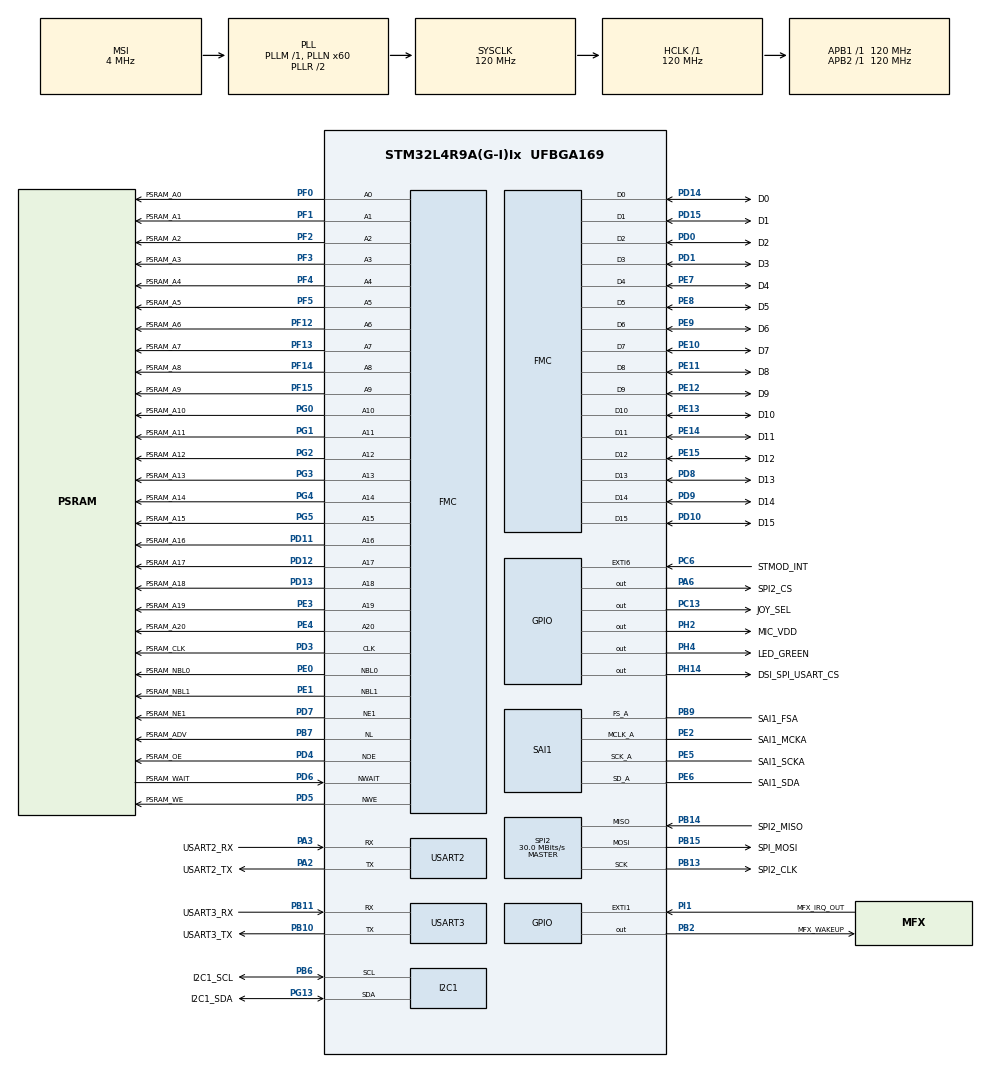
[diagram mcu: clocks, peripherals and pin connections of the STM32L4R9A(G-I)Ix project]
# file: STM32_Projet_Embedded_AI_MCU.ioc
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DSIHOST_CKN.GPIO_Label=DSI_CK_N
DSIHOST_CKN.Signal=DSIHOST_CKN
DSIHOST_CKP.GPIO_Label=DSI_CK_P
DSIHOST_CKP.Signal=DSIHOST_CKP
DSIHOST_D0N.GPIO_Label=DSI_D0_N
DSIHOST_D0N.Signal=DSIHOST_D0N
DSIHOST_D0P.GPIO_Label=DSI_D0_P
DSIHOST_D0P.Signal=DSIHOST_D0P
DSIHOST_D1N.GPIO_Label=DSI_D1_N
DSIHOST_D1N.Signal=DSIHOST_D1N
DSIHOST_D1P.GPIO_Label=DSI_D1_P
DSIHOST_D1P.Signal=DSIHOST_D1P
I2C1.Timing=0x30A175AB
Mcu.Family=STM32L4
Mcu.Name=STM32L4R9A(G-I)Ix
Mcu.Package=UFBGA169
NVIC.PriorityGroup=NVIC_PRIORITYGROUP_4
PA0.GPIO_Label=ARD_A4
PA0.Signal=ADCx_IN5
PA1.GPIO_Label=ARD_D5
PA1.Signal=S_TIM5_CH2
PA10.GPIO_Label=USB_OTGFS_ID
PA10.Signal=USB_OTG_FS_ID
PA11.GPIO_Label=USB_OTGFS_DM
PA11.Signal=USB_OTG_FS_DM
PA12.GPIO_Label=USB_OTG_FS_DP
PA12.Signal=USB_OTG_FS_DP
PA13\ (JTMS/SWDIO).GPIO_Label=SWDIO
PA13\ (JTMS/SWDIO).Mode=Serial_Wire
PA13\ (JTMS/SWDIO).Signal=SYS_JTMS-SWDIO
PA14\ (JTCK/SWCLK).GPIO_Label=SWCLK
PA14\ (JTCK/SWCLK).Mode=Serial_Wire
PA14\ (JTCK/SWCLK).Signal=SYS_JTCK-SWCLK
PA15\ (JTDI).GPIO_Label=USART3_RTS
PA15\ (JTDI).Signal=USART3_RTS
PA2.GPIO_Label=USART2_TX
PA2.Mode=Asynchronous
PA2.Signal=USART2_TX
PA3.GPIO_Label=USART2_RX
PA3.Mode=Asynchronous
PA3.Signal=USART2_RX
PA4.GPIO_Label=DCMI_HSYNC
PA4.Signal=DCMI_HSYNC
PA5.GPIO_Label=STMOD_PWM
PA5.Signal=S_TIM2_CH1
PA6.GPIO_Label=SPI2_CS
PA6.Signal=GPIO_Output
PA7.GPIO_Label=ARD_A0
PA7.Signal=ADCx_IN12
PA9.GPIO_Label=USB_OTGFS_VBUS
PA9.Signal=USB_OTG_FS_VBUS
PB0.GPIO_Label=ARD_A3
PB0.Signal=ADCx_IN15
PB10.GPIO_Label=USART3_TX
PB10.Mode=Asynchronous
PB10.Signal=USART3_TX
PB11.GPIO_Label=USART3_RX
PB11.Mode=Asynchronous
PB11.Signal=USART3_RX
PB12.GPIO_Label=DFDATIN1
PB12.Signal=S_DATAIN1DFSDM1
PB13.GPIO_Label=SPI2_CLK
PB13.Mode=Full_Duplex_Master
PB13.Signal=SPI2_SCK
PB14.GPIO_Label=SPI2_MISO
PB14.Mode=Full_Duplex_Master
PB14.Signal=SPI2_MISO
PB15.GPIO_Label=SPI_MOSI
PB15.Mode=Full_Duplex_Master
PB15.Signal=SPI2_MOSI
PB2.GPIO_Label=MFX_WAKEUP
PB2.Signal=GPIO_Output
PB3\ (JTDO/TRACESWO).GPIO_Label=SWO
PB3\ (JTDO/TRACESWO).Signal=SYS_JTDO-SWO
PB4\ (NJTRST).GPIO_Label=ARD_D6
PB4\ (NJTRST).Signal=S_TIM3_CH1
PB5.GPIO_Label=SAI1_SDB
PB5.Signal=SAI1_SD_B
PB6.GPIO_Label=I2C1_SCL
PB6.GPIO_Pu=GPIO_PULLUP
PB6.Mode=I2C
PB6.Signal=I2C1_SCL
PB7.GPIO_Label=PSRAM_ADV
PB7.Signal=FMC_NL
PB9.GPIO_Label=SAI1_FSA
PB9.Mode=SAI_A_MasterWithClock
PB9.Signal=SAI1_FS_A
PC0.GPIO_Label=ARD_D0
PC0.Signal=LPUART1_RX
PC1.GPIO_Label=ARD_D1
PC1.Signal=LPUART1_TX
PC10.GPIO_Label=uSD_D2
PC10.Signal=SDMMC1_D2
PC11.GPIO_Label=uSD_D3
PC11.Signal=SDMMC1_D3
PC12.GPIO_Label=uSD_CLK
PC12.Signal=SDMMC1_CK
PC13.GPIO_Label=JOY_SEL
PC13.Signal=GPIO_Output
PC14-OSC32_IN\ (PC14).Mode=LSE-External-Oscillator
PC14-OSC32_IN\ (PC14).Signal=RCC_OSC32_IN
PC15-OSC32_OUT\ (PC15).Mode=LSE-External-Oscillator
PC15-OSC32_OUT\ (PC15).Signal=RCC_OSC32_OUT
PC2.GPIO_Label=DF_CKOUT
PC2.Signal=S_CKOUTDFSDM1
PC3.GPIO_Label=ARD_A2
PC3.Signal=ADCx_IN4
PC4.GPIO_Label=ARD_A1
PC4.Signal=ADCx_IN13
PC6.GPIO_Label=STMOD_INT
PC6.Signal=GPXTI6
PC7.GPIO_Label=DFDATIN3
PC7.Signal=S_DATAIN3DFSDM1
PC8.GPIO_Label=uSD_D0
PC8.Signal=SDMMC1_D0
PC9.GPIO_Label=uSD_D1
PC9.Signal=SDMMC1_D1
PD0.GPIO_Label=D2
PD0.Signal=FMC_D2_DA2
PD1.GPIO_Label=D3
PD1.Signal=FMC_D3_DA3
PD10.GPIO_Label=D15
PD10.Signal=FMC_D15_DA15
PD11.GPIO_Label=PSRAM_A16
PD11.Signal=FMC_A16_CLE
PD12.GPIO_Label=PSRAM_A17
PD12.Signal=FMC_A17_ALE
PD13.GPIO_Label=PSRAM_A18
PD13.Signal=FMC_A18
PD14.GPIO_Label=D0
PD14.Signal=FMC_D0_DA0
PD15.GPIO_Label=D1
PD15.Signal=FMC_D1_DA1
PD2.GPIO_Label=uSD_CMD
PD2.Signal=SDMMC1_CMD
PD3.GPIO_Label=PSRAM_CLK
PD3.Signal=FMC_CLK
PD4.GPIO_Label=PSRAM_OE
PD4.Signal=FMC_NOE
PD5.GPIO_Label=PSRAM_WE
PD5.Signal=FMC_NWE
PD6.GPIO_Label=PSRAM_WAIT
PD6.Signal=FMC_NWAIT
PD7.GPIO_Label=PSRAM_NE1
PD7.Mode=NorPsramChipSelect1_1
PD7.Signal=FMC_NE1
PD8.GPIO_Label=D13
PD8.Signal=FMC_D13_DA13
PD9.GPIO_Label=D14
PD9.Signal=FMC_D14_DA14
PE0.GPIO_Label=PSRAM_NBL0
PE0.Signal=FMC_NBL0
PE1.GPIO_Label=PSRAM_NBL1
PE1.Signal=FMC_NBL1
PE10.GPIO_Label=D7
PE10.Signal=FMC_D7_DA7
PE11.GPIO_Label=D8
PE11.Signal=FMC_D8_DA8
PE12.GPIO_Label=D9
PE12.Signal=FMC_D9_DA9
PE13.GPIO_Label=D10
PE13.Signal=FMC_D10_DA10
PE14.GPIO_Label=D11
PE14.Signal=FMC_D11_DA11
PE15.GPIO_Label=D12
PE15.Signal=FMC_D12_DA12
PE2.GPIO_Label=SAI1_MCKA
PE2.Mode=SAI_A_MasterWithClock
PE2.Signal=SAI1_MCLK_A
PE3.GPIO_Label=PSRAM_A19
PE3.Signal=FMC_A19
PE4.GPIO_Label=PSRAM_A20
PE4.Signal=FMC_A20
PE5.GPIO_Label=SAI1_SCKA
PE5.Mode=SAI_A_MasterWithClock
PE5.Signal=SAI1_SCK_A
PE6.GPIO_Label=SAI1_SDA
PE6.Mode=SAI_A_MasterWithClock
PE6.Signal=SAI1_SD_A
PE7.GPIO_Label=D4
PE7.Signal=FMC_D4_DA4
PE8.GPIO_Label=D5
PE8.Signal=FMC_D5_DA5
PE9.GPIO_Label=D6
PE9.Signal=FMC_D6_DA6
PF0.GPIO_Label=PSRAM_A0
PF0.Signal=FMC_A0
PF1.GPIO_Label=PSRAM_A1
PF1.Signal=FMC_A1
PF11.GPIO_Label=DSI_TE
PF11.Signal=DSIHOST_TE
PF12.GPIO_Label=PSRAM_A6
PF12.Signal=FMC_A6
PF13.GPIO_Label=PSRAM_A7
PF13.Signal=FMC_A7
PF14.GPIO_Label=PSRAM_A8
PF14.Signal=FMC_A8
PF15.GPIO_Label=PSRAM_A9
PF15.Signal=FMC_A9
PF2.GPIO_Label=PSRAM_A2
PF2.Signal=FMC_A2
PF3.GPIO_Label=PSRAM_A3
PF3.Signal=FMC_A3
PF4.GPIO_Label=PSRAM_A4
PF4.Signal=FMC_A4
PF5.GPIO_Label=PSRAM_A5
PF5.Signal=FMC_A5
PG0.GPIO_Label=PSRAM_A10
PG0.Signal=FMC_A10
PG1.GPIO_Label=PSRAM_A11
PG1.Signal=FMC_A11
PG10.GPIO_Label=OCTOSPIM_P2_IO7
PG10.Signal=OCTOSPIM_P2_IO7
PG12.GPIO_Label=OCTOSPIM_P2_CS
PG12.Signal=OCTOSPIM_P2_NCS
PG13.GPIO_Label=I2C1_SDA
PG13.GPIO_Pu=GPIO_PULLUP
PG13.Mode=I2C
PG13.Signal=I2C1_SDA
PG15.GPIO_Label=OCTOSPIM_P2_DQS
PG15.Signal=OCTOSPIM_P2_DQS
PG2.GPIO_Label=PSRAM_A12
PG2.Signal=FMC_A12
PG3.GPIO_Label=PSRAM_A13
PG3.Signal=FMC_A13
PG4.GPIO_Label=PSRAM_A14
PG4.Signal=FMC_A14
PG5.GPIO_Label=PSRAM_A15
PG5.Signal=FMC_A15
PG7.GPIO_Label=ARD_15
PG7.Signal=I2C3_SCL
PG8.GPIO_Label=ARD_14
PG8.Signal=I2C3_SDA
PG9.GPIO_Label=OCTOSPIM_P2_IO6
PG9.Signal=OCTOSPIM_P2_IO6
PH0-OSC_IN\ (PH0).Mode=HSE-External-Oscillator
PH0-OSC_IN\ (PH0).Signal=RCC_OSC_IN
PH1-OSC_OUT\ (PH1).Mode=HSE-External-Oscillator
PH1-OSC_OUT\ (PH1).Signal=RCC_OSC_OUT
PH10.GPIO_Label=OCTOSPIM_P2_IO5
PH10.Signal=OCTOSPIM_P2_IO5
PH11.GPIO_Label=DCMI_D2
PH11.Signal=DCMI_D2
PH12.GPIO_Label=DCMI_D3
PH12.Signal=DCMI_D3
PH13.GPIO_Label=ARD_D9
PH13.Signal=TIM8_CH1N
PH14.GPIO_Label=DSI_SPI_USART_CS
PH14.Signal=GPIO_Output
PH2.GPIO_Label=MIC_VDD
PH2.Signal=GPIO_Output
PH4.GPIO_Label=LED_GREEN
PH4.Signal=GPIO_Output
PH5.GPIO_Label=DCMI_PIXCLK
PH5.Signal=DCMI_PIXCLK
PH8.GPIO_Label=OCTOSPI_P2_IO3
PH8.Signal=OCTOSPIM_P2_IO3
PH9.GPIO_Label=OCTOPSIM_P2_IO4
PH9.Signal=OCTOSPIM_P2_IO4
PI0.GPIO_Label=ARD_10
PI0.Signal=SPI2_NSS
PI1.GPIO_Label=MFX_IRQ_OUT
PI1.Signal=GPXTI1
PI10.GPIO_Label=OCTOSPIM_P2_IO1
PI10.Signal=OCTOSPIM_P2_IO1
PI11.GPIO_Label=OCTOSPIM_P2_IO0
PI11.Signal=OCTOSPIM_P2_IO0
PI4.GPIO_Label=DCMI_D5
PI4.Signal=DCMI_D5
PI5.GPIO_Label=DCMI_VSYNC
PI5.Signal=DCMI_VSYNC
PI6.GPIO_Label=OCTOSPIM_P2_CLK
PI6.Signal=OCTOSPIM_P2_CLK
PI7.GPIO_Label=DCMI_D7
PI7.Signal=DCMI_D7
PI9.GPIO_Label=OCTOSPIM_P2_IO2
PI9.Signal=OCTOSPIM_P2_IO2
ProjectManager.HeapSize=0x800
ProjectManager.StackSize=0x800
ProjectManager.TargetToolchain=STM32CubeIDE
RCC.ADCFreq_Value=32000000
RCC.AHBFreq_Value=120000000
RCC.APB1Freq_Value=120000000
RCC.APB1TimFreq_Value=120000000
RCC.APB2Freq_Value=120000000
RCC.APB2TimFreq_Value=120000000
RCC.CK48CLockSelection=RCC_USBCLKSOURCE_HSI48
RCC.CortexFreq_Value=120000000
RCC.HCLKFreq_Value=120000000
RCC.HSE_VALUE=16000000
RCC.HSI48_VALUE=48000000
RCC.HSI_VALUE=16000000
RCC.MSI_VALUE=4000000
RCC.PLLDSINDIV=32
RCC.PLLN=60
RCC.PLLP=RCC_PLLP_DIV5
RCC.PLLSAI1N=16
RCC.SYSCLKFreq_VALUE=120000000
RCC.SYSCLKSource=RCC_SYSCLKSOURCE_PLLCLK
RCC.USBFreq_Value=48000000
RCC.VCOOutputFreq_Value=240000000
SAI1.Instance-SAI_A_MasterWithClock=SAI$Index_Block_A
SAI1.MClockEnable-SAI_A_MasterWithClock=SAI_MASTERCLOCK_ENABLE
SAI1.Synchro-SAI_A_MasterWithClock=SAI_ASYNCHRONOUS
SAI1.VirtualMode-SAI_A_MasterWithClock=VM_MASTER
SH.ADCx_IN12.0=ADC1_IN12
SH.ADCx_IN13.0=ADC1_IN13
SH.ADCx_IN15.0=ADC1_IN15
SH.ADCx_IN4.0=ADC1_IN4
SH.ADCx_IN5.0=ADC1_IN5
SH.FMC_A0.0=FMC_A0,21b-a1
SH.FMC_A1.0=FMC_A1,21b-a1
SH.FMC_A10.0=FMC_A10,21b-a1
SH.FMC_A11.0=FMC_A11,21b-a1
SH.FMC_A12.0=FMC_A12,21b-a1
SH.FMC_A13.0=FMC_A13,21b-a1
SH.FMC_A14.0=FMC_A14,21b-a1
SH.FMC_A15.0=FMC_A15,21b-a1
SH.FMC_A16_CLE.0=FMC_A16,21b-a1
SH.FMC_A17_ALE.0=FMC_A17,21b-a1
SH.FMC_A18.0=FMC_A18,21b-a1
SH.FMC_A19.0=FMC_A19,21b-a1
SH.FMC_A2.0=FMC_A2,21b-a1
SH.FMC_A20.0=FMC_A20,21b-a1
SH.FMC_A3.0=FMC_A3,21b-a1
SH.FMC_A4.0=FMC_A4,21b-a1
SH.FMC_A5.0=FMC_A5,21b-a1
SH.FMC_A6.0=FMC_A6,21b-a1
SH.FMC_A7.0=FMC_A7,21b-a1
SH.FMC_A8.0=FMC_A8,21b-a1
SH.FMC_A9.0=FMC_A9,21b-a1
SH.FMC_CLK.0=FMC_CLK,BurstReadWrite1
SH.FMC_D0_DA0.0=FMC_D0,16b-d1
SH.FMC_D10_DA10.0=FMC_D10,16b-d1
SH.FMC_D11_DA11.0=FMC_D11,16b-d1
SH.FMC_D12_DA12.0=FMC_D12,16b-d1
SH.FMC_D13_DA13.0=FMC_D13,16b-d1
SH.FMC_D14_DA14.0=FMC_D14,16b-d1
SH.FMC_D15_DA15.0=FMC_D15,16b-d1
SH.FMC_D1_DA1.0=FMC_D1,16b-d1
SH.FMC_D2_DA2.0=FMC_D2,16b-d1
SH.FMC_D3_DA3.0=FMC_D3,16b-d1
SH.FMC_D4_DA4.0=FMC_D4,16b-d1
SH.FMC_D5_DA5.0=FMC_D5,16b-d1
SH.FMC_D6_DA6.0=FMC_D6,16b-d1
SH.FMC_D7_DA7.0=FMC_D7,16b-d1
SH.FMC_D8_DA8.0=FMC_D8,16b-d1
SH.FMC_D9_DA9.0=FMC_D9,16b-d1
SH.FMC_NBL0.0=FMC_NBL0,2ByteEnable1
SH.FMC_NBL1.0=FMC_NBL1,2ByteEnable1
SH.FMC_NL.0=FMC_NL,AddressValid1
SH.FMC_NOE.0=FMC_NOE,Psram1
SH.FMC_NWAIT.0=FMC_NWAIT,SynchronousWait1
SH.FMC_NWE.0=FMC_NWE,Psram1
SH.S_CKOUTDFSDM1.0=DFSDM1_CKOUT
SH.S_DATAIN1DFSDM1.0=DFSDM1_DATIN1
SH.S_DATAIN3DFSDM1.0=DFSDM1_DATIN3
SH.S_TIM2_CH1.0=TIM2_CH1
SH.S_TIM3_CH1.0=TIM3_CH1
SH.S_TIM5_CH2.0=TIM5_CH2
SPI2.BaudRatePrescaler=SPI_BAUDRATEPRESCALER_4
SPI2.CalculateBaudRate=30.0 MBits/s
SPI2.Direction=SPI_DIRECTION_2LINES
SPI2.Mode=SPI_MODE_MASTER
SPI2.VirtualType=VM_MASTER
STMicroelectronics.X-CUBE-AI.10.2.1.ActivationBufferSizeList=8164
STMicroelectronics.X-CUBE-AI.10.2.1.ActivationBuffers=pool0
STMicroelectronics.X-CUBE-AI.10.2.1.ActivationNames=pool0
STMicroelectronics.X-CUBE-AI.10.2.1.ActivationSizes=AI_MLP_MNIST_PROJET_DATA_ACTIVATION_1_SIZE
STMicroelectronics.X-CUBE-AI.10.2.1.ApplicationCcDeviceJjApplication=ApplicationTemplate
STMicroelectronics.X-CUBE-AI.10.2.1.HeapSize=0x800
STMicroelectronics.X-CUBE-AI.10.2.1.InternalRamActivationBufferMaxSize=AI_MLP_MNIST_PROJET_DATA_ACTIVATIONS_SIZE
STMicroelectronics.X-CUBE-AI.10.2.1.LatestDirectoryUsed-bec54e313666f811863a96fbc236fbb6e126a35f0ca2705b14571c2bcad92c82=C\:\\Users\\foltz\\Documents\\ISMIN\\3A\\Embedded_Systems\\Embedded_Neural_Network_on_MCU
STMicroelectronics.X-CUBE-AI.10.2.1.MaximumNumberOfInputLayer=1
STMicroelectronics.X-CUBE-AI.10.2.1.MaximumNumberOfOutputLayer=1
STMicroelectronics.X-CUBE-AI.10.2.1.MaximumSizeOfInputLayer=1
STMicroelectronics.X-CUBE-AI.10.2.1.MaximumSizeOfOutputLayer=1
STMicroelectronics.X-CUBE-AI.10.2.1.ModelActualCompression-bec54e313666f811863a96fbc236fbb6e126a35f0ca2705b14571c2bcad92c82=0.0
STMicroelectronics.X-CUBE-AI.10.2.1.ModelCompression-bec54e313666f811863a96fbc236fbb6e126a35f0ca2705b14571c2bcad92c82=Medium
STMicroelectronics.X-CUBE-AI.10.2.1.ModelFlashOccupation-bec54e313666f811863a96fbc236fbb6e126a35f0ca2705b14571c2bcad92c82=334080
STMicroelectronics.X-CUBE-AI.10.2.1.ModelHashList=bec54e313666f811863a96fbc236fbb6e126a35f0ca2705b14571c2bcad92c82
STMicroelectronics.X-CUBE-AI.10.2.1.ModelKind-bec54e313666f811863a96fbc236fbb6e126a35f0ca2705b14571c2bcad92c82=KERAS
STMicroelectronics.X-CUBE-AI.10.2.1.ModelMacc-bec54e313666f811863a96fbc236fbb6e126a35f0ca2705b14571c2bcad92c82=576160
STMicroelectronics.X-CUBE-AI.10.2.1.ModelName-bec54e313666f811863a96fbc236fbb6e126a35f0ca2705b14571c2bcad92c82=mlp_mnist_projet
STMicroelectronics.X-CUBE-AI.10.2.1.ModelNameList=mlp_mnist_projet
STMicroelectronics.X-CUBE-AI.10.2.1.ModelRamOccupation-bec54e313666f811863a96fbc236fbb6e126a35f0ca2705b14571c2bcad92c82=8164
STMicroelectronics.X-CUBE-AI.10.2.1.ModelStructureFile-bec54e313666f811863a96fbc236fbb6e126a35f0ca2705b14571c2bcad92c82=C\:\\Users\\foltz\\Documents\\ISMIN\\3A\\Embedded_Systems\\Embedded_Neural_Network_on_MCU\\Projet_Embedded_AI_MCU\\models\\5dense-mnist-10class-finetuned.h5
STMicroelectronics.X-CUBE-AI.10.2.1.ModelType-bec54e313666f811863a96fbc236fbb6e126a35f0ca2705b14571c2bcad92c82=STM32Cube.AI MCU runtime
STMicroelectronics.X-CUBE-AI.10.2.1.ReadyForCodeGeneration=true
STMicroelectronics.X-CUBE-AI.10.2.1.StackSize=0x800
STMicroelectronics.X-CUBE-AI.10.2.1.ValidationInputFile-bec54e313666f811863a96fbc236fbb6e126a35f0ca2705b14571c2bcad92c82=C\:\\Users\\foltz\\Documents\\ISMIN\\3A\\Embedded_Systems\\Embedded_Neural_Network_on_MCU\\MNIST_xtest_NN_C2_16_10.npy
STMicroelectronics.X-CUBE-AI.10.2.1.ValidationInputFileHistory-bec54e313666f811863a96fbc236fbb6e126a35f0ca2705b14571c2bcad92c82=C\:\\Users\\foltz\\Documents\\ISMIN\\3A\\Embedded_Systems\\Embedded_Neural_Network_on_MCU\\MNIST_xtest_NN_C2_16_10.npy,C\:\\Users\\foltz\\Documents\\ISMIN\\3A\\Embedded_Systems\\Embedded_Neural_Network_on_MCU\\MNIST_xtest_NN_C2_16_10.npy
STMicroelectronics.X-CUBE-AI.10.2.1.ValidationOutputFile-bec54e313666f811863a96fbc236fbb6e126a35f0ca2705b14571c2bcad92c82=C\:\\Users\\foltz\\Documents\\ISMIN\\3A\\Embedded_Systems\\Embedded_Neural_Network_on_MCU\\MNIST_ytest_NN_C2_16_10.npy
STMicroelectronics.X-CUBE-AI.10.2.1.ValidationOutputFileHistory-bec54e313666f811863a96fbc236fbb6e126a35f0ca2705b14571c2bcad92c82=C\:\\Users\\foltz\\Documents\\ISMIN\\3A\\Embedded_Systems\\Embedded_Neural_Network_on_MCU\\MNIST_ytest_NN_C2_16_10.npy,C\:\\Users\\foltz\\Documents\\ISMIN\\3A\\Embedded_Systems\\Embedded_Neural_Network_on_MCU\\MNIST_ytest_NN_C2_16_10.npy
STMicroelectronics.X-CUBE-AI.10.2.1.WorkingBufferStartAddrList=0xFFFFFFFF
STMicroelectronics.X-CUBE-AI.10.2.1.XAaCUBEAaAICcArtificialOoIntelligenceJjCore=true
STMicroelectronics.X-CUBE-AI.10.2.1.copyWeightToRam=false
STMicroelectronics.X-CUBE-AI.10.2.1.copyWeightToRam-bec54e313666f811863a96fbc236fbb6e126a35f0ca2705b14571c2bcad92c82=false
STMicroelectronics.X-CUBE-AI.10.2.1.customLayerConfigEnabled=false
STMicroelectronics.X-CUBE-AI.10.2.1.customLayerConfigEnabled-bec54e313666f811863a96fbc236fbb6e126a35f0ca2705b14571c2bcad92c82=false
STMicroelectronics.X-CUBE-AI.10.2.1.noOnnxIoTranspose=false
STMicroelectronics.X-CUBE-AI.10.2.1.noOnnxIoTranspose-bec54e313666f811863a96fbc236fbb6e126a35f0ca2705b14571c2bcad92c82=false
STMicroelectronics.X-CUBE-AI.10.2.1.useInputAllocation=true
STMicroelectronics.X-CUBE-AI.10.2.1.useInputAllocation-bec54e313666f811863a96fbc236fbb6e126a35f0ca2705b14571c2bcad92c82=true
STMicroelectronics.X-CUBE-AI.10.2.1.useOutputAllocation=true
STMicroelectronics.X-CUBE-AI.10.2.1.useOutputAllocation-bec54e313666f811863a96fbc236fbb6e126a35f0ca2705b14571c2bcad92c82=true
USART2.VirtualMode-Asynchronous=VM_ASYNC
USART3.VirtualMode-Asynchronous=VM_ASYNC
VP_STMicroelectronics.X-CUBE-AI_VS_ArtificialOoIntelligenceJjXAaCUBEAaAI_10.2.1.Mode=ArtificialOoIntelligenceJjXAaCUBEAaAI
VP_STMicroelectronics.X-CUBE-AI_VS_DeviceJjApplication_10.2.1.Mode=DeviceJjApplication
board=STM32L4R9I-DISCO

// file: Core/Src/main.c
/* USER CODE BEGIN Header */
/**
  ******************************************************************************
  * @file           : main.c
  * @brief          : Main program body
  ******************************************************************************
  * @attention
  *
  * Copyright (c) 2026 STMicroelectronics.
  * All rights reserved.
  *
  * This software is licensed under terms that can be found in the LICENSE file
  * in the root directory of this software component.
  * If no LICENSE file comes with this software, it is provided AS-IS.
  *
  ******************************************************************************
  */
/* USER CODE END Header */
#include "main.h"
#include "app_x-cube-ai.h"

I2C_HandleTypeDef hi2c1;

SAI_HandleTypeDef hsai_BlockA1;

SPI_HandleTypeDef hspi2;

UART_HandleTypeDef huart2;
UART_HandleTypeDef huart3;

SRAM_HandleTypeDef hsram1;

void SystemClock_Config(void);
static void MX_GPIO_Init(void);
static void MX_FMC_Init(void);
static void MX_I2C1_Init(void);
static void MX_SAI1_Init(void);
static void MX_SPI2_Init(void);
static void MX_USART2_UART_Init(void);
static void MX_USART3_UART_Init(void);
/* USER CODE BEGIN PFP */
void AIfES_Init(void);
void AIfES_Process(void);
/* USER CODE END PFP */

int main(void)
{

  /* MCU Configuration--------------------------------------------------------*/

  /* Reset of all peripherals, Initializes the Flash interface and the Systick. */
  HAL_Init();

  /* Configure the system clock */
  SystemClock_Config();

  /* Initialize all configured peripherals */
  MX_GPIO_Init();
  MX_FMC_Init();
  MX_I2C1_Init();
  MX_SAI1_Init();
  MX_SPI2_Init();
  MX_USART2_UART_Init();
  MX_USART3_UART_Init();
  MX_X_CUBE_AI_Init();
  /* USER CODE BEGIN 2 */
  AIfES_Init();
  AIfES_Process(); //ne rend jamais la main donc pas besoin de rentrer dans le while, la focntion contient sa propre boucle infinie

  /* USER CODE END 2 */

  /* Infinite loop */
  while (1)
  {

  MX_X_CUBE_AI_Process();
  }
}

void SystemClock_Config(void)
{
  RCC_OscInitTypeDef RCC_OscInitStruct = {0};
  RCC_ClkInitTypeDef RCC_ClkInitStruct = {0};

  /** Configure the main internal regulator output voltage
  */
  if (HAL_PWREx_ControlVoltageScaling(PWR_REGULATOR_VOLTAGE_SCALE1_BOOST) != HAL_OK)
  {
    Error_Handler();
  }

  /** Initializes the RCC Oscillators according to the specified parameters
  * in the RCC_OscInitTypeDef structure.
  */
  RCC_OscInitStruct.OscillatorType = RCC_OSCILLATORTYPE_MSI;
  RCC_OscInitStruct.MSIState = RCC_MSI_ON;
  RCC_OscInitStruct.MSICalibrationValue = 0;
  RCC_OscInitStruct.MSIClockRange = RCC_MSIRANGE_6;
  RCC_OscInitStruct.PLL.PLLState = RCC_PLL_ON;
  RCC_OscInitStruct.PLL.PLLSource = RCC_PLLSOURCE_MSI;
  RCC_OscInitStruct.PLL.PLLM = 1;
  RCC_OscInitStruct.PLL.PLLN = 60;
  RCC_OscInitStruct.PLL.PLLP = RCC_PLLP_DIV5;
  RCC_OscInitStruct.PLL.PLLQ = RCC_PLLQ_DIV2;
  RCC_OscInitStruct.PLL.PLLR = RCC_PLLR_DIV2;
  if (HAL_RCC_OscConfig(&RCC_OscInitStruct) != HAL_OK)
  {
    Error_Handler();
  }

  /** Initializes the CPU, AHB and APB buses clocks
  */
  RCC_ClkInitStruct.ClockType = RCC_CLOCKTYPE_HCLK|RCC_CLOCKTYPE_SYSCLK
                              |RCC_CLOCKTYPE_PCLK1|RCC_CLOCKTYPE_PCLK2;
  RCC_ClkInitStruct.SYSCLKSource = RCC_SYSCLKSOURCE_PLLCLK;
  RCC_ClkInitStruct.AHBCLKDivider = RCC_SYSCLK_DIV1;
  RCC_ClkInitStruct.APB1CLKDivider = RCC_HCLK_DIV1;
  RCC_ClkInitStruct.APB2CLKDivider = RCC_HCLK_DIV1;

  if (HAL_RCC_ClockConfig(&RCC_ClkInitStruct, FLASH_LATENCY_5) != HAL_OK)
  {
    Error_Handler();
  }
}

static void MX_I2C1_Init(void)
{

  hi2c1.Instance = I2C1;
  hi2c1.Init.Timing = 0x30A175AB;
  hi2c1.Init.OwnAddress1 = 0;
  hi2c1.Init.AddressingMode = I2C_ADDRESSINGMODE_7BIT;
  hi2c1.Init.DualAddressMode = I2C_DUALADDRESS_DISABLE;
  hi2c1.Init.OwnAddress2 = 0;
  hi2c1.Init.OwnAddress2Masks = I2C_OA2_NOMASK;
  hi2c1.Init.GeneralCallMode = I2C_GENERALCALL_DISABLE;
  hi2c1.Init.NoStretchMode = I2C_NOSTRETCH_DISABLE;
  if (HAL_I2C_Init(&hi2c1) != HAL_OK)
  {
    Error_Handler();
  }

  /** Configure Analogue filter
  */
  if (HAL_I2CEx_ConfigAnalogFilter(&hi2c1, I2C_ANALOGFILTER_ENABLE) != HAL_OK)
  {
    Error_Handler();
  }

  /** Configure Digital filter
  */
  if (HAL_I2CEx_ConfigDigitalFilter(&hi2c1, 0) != HAL_OK)
  {
    Error_Handler();
  }

}

static void MX_SAI1_Init(void)
{

  hsai_BlockA1.Instance = SAI1_Block_A;
  hsai_BlockA1.Init.Protocol = SAI_FREE_PROTOCOL;
  hsai_BlockA1.Init.AudioMode = SAI_MODEMASTER_TX;
  hsai_BlockA1.Init.DataSize = SAI_DATASIZE_8;
  hsai_BlockA1.Init.FirstBit = SAI_FIRSTBIT_MSB;
  hsai_BlockA1.Init.ClockStrobing = SAI_CLOCKSTROBING_FALLINGEDGE;
  hsai_BlockA1.Init.Synchro = SAI_ASYNCHRONOUS;
  hsai_BlockA1.Init.OutputDrive = SAI_OUTPUTDRIVE_DISABLE;
  hsai_BlockA1.Init.NoDivider = SAI_MASTERDIVIDER_ENABLE;
  hsai_BlockA1.Init.MckOverSampling = SAI_MCK_OVERSAMPLING_DISABLE;
  hsai_BlockA1.Init.FIFOThreshold = SAI_FIFOTHRESHOLD_EMPTY;
  hsai_BlockA1.Init.AudioFrequency = SAI_AUDIO_FREQUENCY_192K;
  hsai_BlockA1.Init.SynchroExt = SAI_SYNCEXT_DISABLE;
  hsai_BlockA1.Init.MonoStereoMode = SAI_STEREOMODE;
  hsai_BlockA1.Init.CompandingMode = SAI_NOCOMPANDING;
  hsai_BlockA1.Init.TriState = SAI_OUTPUT_NOTRELEASED;
  hsai_BlockA1.Init.PdmInit.Activation = DISABLE;
  hsai_BlockA1.Init.PdmInit.MicPairsNbr = 0;
  hsai_BlockA1.Init.PdmInit.ClockEnable = SAI_PDM_CLOCK1_ENABLE;
  hsai_BlockA1.FrameInit.FrameLength = 8;
  hsai_BlockA1.FrameInit.ActiveFrameLength = 1;
  hsai_BlockA1.FrameInit.FSDefinition = SAI_FS_STARTFRAME;
  hsai_BlockA1.FrameInit.FSPolarity = SAI_FS_ACTIVE_LOW;
  hsai_BlockA1.FrameInit.FSOffset = SAI_FS_FIRSTBIT;
  hsai_BlockA1.SlotInit.FirstBitOffset = 0;
  hsai_BlockA1.SlotInit.SlotSize = SAI_SLOTSIZE_DATASIZE;
  hsai_BlockA1.SlotInit.SlotNumber = 1;
  hsai_BlockA1.SlotInit.SlotActive = 0x00000000;
  if (HAL_SAI_Init(&hsai_BlockA1) != HAL_OK)
  {
    Error_Handler();
  }

}

static void MX_SPI2_Init(void)
{

  /* SPI2 parameter configuration*/
  hspi2.Instance = SPI2;
  hspi2.Init.Mode = SPI_MODE_MASTER;
  hspi2.Init.Direction = SPI_DIRECTION_2LINES;
  hspi2.Init.DataSize = SPI_DATASIZE_4BIT;
  hspi2.Init.CLKPolarity = SPI_POLARITY_LOW;
  hspi2.Init.CLKPhase = SPI_PHASE_1EDGE;
  hspi2.Init.NSS = SPI_NSS_SOFT;
  hspi2.Init.BaudRatePrescaler = SPI_BAUDRATEPRESCALER_4;
  hspi2.Init.FirstBit = SPI_FIRSTBIT_MSB;
  hspi2.Init.TIMode = SPI_TIMODE_DISABLE;
  hspi2.Init.CRCCalculation = SPI_CRCCALCULATION_DISABLE;
  hspi2.Init.CRCPolynomial = 7;
  hspi2.Init.CRCLength = SPI_CRC_LENGTH_DATASIZE;
  hspi2.Init.NSSPMode = SPI_NSS_PULSE_ENABLE;
  if (HAL_SPI_Init(&hspi2) != HAL_OK)
  {
    Error_Handler();
  }

}

static void MX_USART2_UART_Init(void)
{

  huart2.Instance = USART2;
  huart2.Init.BaudRate = 115200;
  huart2.Init.WordLength = UART_WORDLENGTH_8B;
  huart2.Init.StopBits = UART_STOPBITS_1;
  huart2.Init.Parity = UART_PARITY_NONE;
  huart2.Init.Mode = UART_MODE_TX_RX;
  huart2.Init.HwFlowCtl = UART_HWCONTROL_NONE;
  huart2.Init.OverSampling = UART_OVERSAMPLING_16;
  huart2.Init.OneBitSampling = UART_ONE_BIT_SAMPLE_DISABLE;
  huart2.Init.ClockPrescaler = UART_PRESCALER_DIV1;
  huart2.AdvancedInit.AdvFeatureInit = UART_ADVFEATURE_NO_INIT;
  if (HAL_UART_Init(&huart2) != HAL_OK)
  {
    Error_Handler();
  }
  if (HAL_UARTEx_SetTxFifoThreshold(&huart2, UART_TXFIFO_THRESHOLD_1_8) != HAL_OK)
  {
    Error_Handler();
  }
  if (HAL_UARTEx_SetRxFifoThreshold(&huart2, UART_RXFIFO_THRESHOLD_1_8) != HAL_OK)
  {
    Error_Handler();
  }
  if (HAL_UARTEx_DisableFifoMode(&huart2) != HAL_OK)
  {
    Error_Handler();
  }

}

static void MX_USART3_UART_Init(void)
{

  huart3.Instance = USART3;
  huart3.Init.BaudRate = 115200;
  huart3.Init.WordLength = UART_WORDLENGTH_8B;
  huart3.Init.StopBits = UART_STOPBITS_1;
  huart3.Init.Parity = UART_PARITY_NONE;
  huart3.Init.Mode = UART_MODE_TX_RX;
  huart3.Init.HwFlowCtl = UART_HWCONTROL_NONE;
  huart3.Init.OverSampling = UART_OVERSAMPLING_16;
  huart3.Init.OneBitSampling = UART_ONE_BIT_SAMPLE_DISABLE;
  huart3.Init.ClockPrescaler = UART_PRESCALER_DIV1;
  huart3.AdvancedInit.AdvFeatureInit = UART_ADVFEATURE_NO_INIT;
  if (HAL_UART_Init(&huart3) != HAL_OK)
  {
    Error_Handler();
  }
  if (HAL_UARTEx_SetTxFifoThreshold(&huart3, UART_TXFIFO_THRESHOLD_1_8) != HAL_OK)
  {
    Error_Handler();
  }
  if (HAL_UARTEx_SetRxFifoThreshold(&huart3, UART_RXFIFO_THRESHOLD_1_8) != HAL_OK)
  {
    Error_Handler();
  }
  if (HAL_UARTEx_DisableFifoMode(&huart3) != HAL_OK)
  {
    Error_Handler();
  }

}

/* FMC initialization function */
static void MX_FMC_Init(void)
{

  FMC_NORSRAM_TimingTypeDef Timing = {0};

  /** Perform the SRAM1 memory initialization sequence
  */
  hsram1.Instance = FMC_NORSRAM_DEVICE;
  hsram1.Extended = FMC_NORSRAM_EXTENDED_DEVICE;
  /* hsram1.Init */
  hsram1.Init.NSBank = FMC_NORSRAM_BANK1;
  hsram1.Init.DataAddressMux = FMC_DATA_ADDRESS_MUX_DISABLE;
  hsram1.Init.MemoryType = FMC_MEMORY_TYPE_PSRAM;
  hsram1.Init.MemoryDataWidth = FMC_NORSRAM_MEM_BUS_WIDTH_16;
  hsram1.Init.BurstAccessMode = FMC_BURST_ACCESS_MODE_ENABLE;
  hsram1.Init.WaitSignalPolarity = FMC_WAIT_SIGNAL_POLARITY_LOW;
  hsram1.Init.WaitSignalActive = FMC_WAIT_TIMING_BEFORE_WS;
  hsram1.Init.WriteOperation = FMC_WRITE_OPERATION_DISABLE;
  hsram1.Init.WaitSignal = FMC_WAIT_SIGNAL_ENABLE;
  hsram1.Init.ExtendedMode = FMC_EXTENDED_MODE_DISABLE;
  hsram1.Init.AsynchronousWait = FMC_ASYNCHRONOUS_WAIT_DISABLE;
  hsram1.Init.WriteBurst = FMC_WRITE_BURST_ENABLE;
  hsram1.Init.ContinuousClock = FMC_CONTINUOUS_CLOCK_SYNC_ONLY;
  hsram1.Init.WriteFifo = FMC_WRITE_FIFO_ENABLE;
  hsram1.Init.NBLSetupTime = 0;
  hsram1.Init.PageSize = FMC_PAGE_SIZE_NONE;
  /* Timing */
  Timing.AddressSetupTime = 15;
  Timing.AddressHoldTime = 15;
  Timing.DataSetupTime = 255;
  Timing.DataHoldTime = 0;
  Timing.BusTurnAroundDuration = 15;
  Timing.CLKDivision = 16;
  Timing.DataLatency = 2;
  Timing.AccessMode = FMC_ACCESS_MODE_A;
  /* ExtTiming */

  if (HAL_SRAM_Init(&hsram1, &Timing, NULL) != HAL_OK)
  {
    Error_Handler( );
  }

}

static void MX_GPIO_Init(void)
{
  GPIO_InitTypeDef GPIO_InitStruct = {0};

  /* GPIO Ports Clock Enable */
  __HAL_RCC_GPIOI_CLK_ENABLE();
  __HAL_RCC_GPIOH_CLK_ENABLE();
  __HAL_RCC_GPIOE_CLK_ENABLE();
  __HAL_RCC_GPIOB_CLK_ENABLE();
  __HAL_RCC_GPIOA_CLK_ENABLE();
  __HAL_RCC_GPIOG_CLK_ENABLE();
  HAL_PWREx_EnableVddIO2();
  __HAL_RCC_GPIOD_CLK_ENABLE();
  __HAL_RCC_GPIOC_CLK_ENABLE();
  __HAL_RCC_GPIOF_CLK_ENABLE();

  /*Configure GPIO pin Output Level */
  HAL_GPIO_WritePin(GPIOH, MIC_VDD_Pin|DSI_SPI_USART_CS_Pin|LED_GREEN_Pin, GPIO_PIN_RESET);

  /*Configure GPIO pin Output Level */
  HAL_GPIO_WritePin(JOY_SEL_GPIO_Port, JOY_SEL_Pin, GPIO_PIN_RESET);

  /*Configure GPIO pin Output Level */
  HAL_GPIO_WritePin(SPI2_CS_GPIO_Port, SPI2_CS_Pin, GPIO_PIN_RESET);

  /*Configure GPIO pin Output Level */
  HAL_GPIO_WritePin(MFX_WAKEUP_GPIO_Port, MFX_WAKEUP_Pin, GPIO_PIN_RESET);

  /*Configure GPIO pins : OCTOSPIM_P2_IO1_Pin OCTOSPIM_P2_IO2_Pin OCTOSPIM_P2_CLK_Pin OCTOSPIM_P2_IO0_Pin */
  GPIO_InitStruct.Pin = OCTOSPIM_P2_IO1_Pin|OCTOSPIM_P2_IO2_Pin|OCTOSPIM_P2_CLK_Pin|OCTOSPIM_P2_IO0_Pin;
  GPIO_InitStruct.Mode = GPIO_MODE_AF_PP;
  GPIO_InitStruct.Pull = GPIO_NOPULL;
  GPIO_InitStruct.Speed = GPIO_SPEED_FREQ_VERY_HIGH;
  GPIO_InitStruct.Alternate = GPIO_AF5_OCTOSPIM_P2;
  HAL_GPIO_Init(GPIOI, &GPIO_InitStruct);

  /*Configure GPIO pins : MIC_VDD_Pin DSI_SPI_USART_CS_Pin LED_GREEN_Pin */
  GPIO_InitStruct.Pin = MIC_VDD_Pin|DSI_SPI_USART_CS_Pin|LED_GREEN_Pin;
  GPIO_InitStruct.Mode = GPIO_MODE_OUTPUT_PP;
  GPIO_InitStruct.Pull = GPIO_NOPULL;
  GPIO_InitStruct.Speed = GPIO_SPEED_FREQ_LOW;
  HAL_GPIO_Init(GPIOH, &GPIO_InitStruct);

  /*Configure GPIO pin : ARD_D6_Pin */
  GPIO_InitStruct.Pin = ARD_D6_Pin;
  GPIO_InitStruct.Mode = GPIO_MODE_AF_PP;
  GPIO_InitStruct.Pull = GPIO_NOPULL;
  GPIO_InitStruct.Speed = GPIO_SPEED_FREQ_LOW;
  GPIO_InitStruct.Alternate = GPIO_AF2_TIM3;
  HAL_GPIO_Init(ARD_D6_GPIO_Port, &GPIO_InitStruct);

  /*Configure GPIO pins : DCMI_D7_Pin DCMI_D5_Pin DCMI_VSYNC_Pin */
  GPIO_InitStruct.Pin = DCMI_D7_Pin|DCMI_D5_Pin|DCMI_VSYNC_Pin;
  GPIO_InitStruct.Mode = GPIO_MODE_AF_PP;
  GPIO_InitStruct.Pull = GPIO_NOPULL;
  GPIO_InitStruct.Speed = GPIO_SPEED_FREQ_LOW;
  GPIO_InitStruct.Alternate = GPIO_AF10_DCMI;
  HAL_GPIO_Init(GPIOI, &GPIO_InitStruct);

  /*Configure GPIO pins : OCTOSPIM_P2_IO6_Pin OCTOSPIM_P2_DQS_Pin OCTOSPIM_P2_IO7_Pin OCTOSPIM_P2_CS_Pin */
  GPIO_InitStruct.Pin = OCTOSPIM_P2_IO6_Pin|OCTOSPIM_P2_DQS_Pin|OCTOSPIM_P2_IO7_Pin|OCTOSPIM_P2_CS_Pin;
  GPIO_InitStruct.Mode = GPIO_MODE_AF_PP;
  GPIO_InitStruct.Pull = GPIO_NOPULL;
  GPIO_InitStruct.Speed = GPIO_SPEED_FREQ_VERY_HIGH;
  GPIO_InitStruct.Alternate = GPIO_AF5_OCTOSPIM_P2;
  HAL_GPIO_Init(GPIOG, &GPIO_InitStruct);

  /*Configure GPIO pin : MFX_IRQ_OUT_Pin */
  GPIO_InitStruct.Pin = MFX_IRQ_OUT_Pin;
  GPIO_InitStruct.Mode = GPIO_MODE_IT_RISING;
  GPIO_InitStruct.Pull = GPIO_NOPULL;
  HAL_GPIO_Init(MFX_IRQ_OUT_GPIO_Port, &GPIO_InitStruct);

  /*Configure GPIO pins : DCMI_D3_Pin DCMI_PIXCLK_Pin DCMI_D2_Pin */
  GPIO_InitStruct.Pin = DCMI_D3_Pin|DCMI_PIXCLK_Pin|DCMI_D2_Pin;
  GPIO_InitStruct.Mode = GPIO_MODE_AF_PP;
  GPIO_InitStruct.Pull = GPIO_NOPULL;
  GPIO_InitStruct.Speed = GPIO_SPEED_FREQ_LOW;
  GPIO_InitStruct.Alternate = GPIO_AF10_DCMI;
  HAL_GPIO_Init(GPIOH, &GPIO_InitStruct);

  /*Configure GPIO pin : ARD_D9_Pin */
  GPIO_InitStruct.Pin = ARD_D9_Pin;
  GPIO_InitStruct.Mode = GPIO_MODE_AF_PP;
  GPIO_InitStruct.Pull = GPIO_NOPULL;
  GPIO_InitStruct.Speed = GPIO_SPEED_FREQ_LOW;
  GPIO_InitStruct.Alternate = GPIO_AF3_TIM8;
  HAL_GPIO_Init(ARD_D9_GPIO_Port, &GPIO_InitStruct);

  /*Configure GPIO pins : OCTOPSIM_P2_IO4_Pin OCTOSPIM_P2_IO5_Pin OCTOSPI_P2_IO3_Pin */
  GPIO_InitStruct.Pin = OCTOPSIM_P2_IO4_Pin|OCTOSPIM_P2_IO5_Pin|OCTOSPI_P2_IO3_Pin;
  GPIO_InitStruct.Mode = GPIO_MODE_AF_PP;
  GPIO_InitStruct.Pull = GPIO_NOPULL;
  GPIO_InitStruct.Speed = GPIO_SPEED_FREQ_VERY_HIGH;
  GPIO_InitStruct.Alternate = GPIO_AF5_OCTOSPIM_P2;
  HAL_GPIO_Init(GPIOH, &GPIO_InitStruct);

  /*Configure GPIO pin : uSD_CMD_Pin */
  GPIO_InitStruct.Pin = uSD_CMD_Pin;
  GPIO_InitStruct.Mode = GPIO_MODE_AF_PP;
  GPIO_InitStruct.Pull = GPIO_NOPULL;
  GPIO_InitStruct.Speed = GPIO_SPEED_FREQ_VERY_HIGH;
  GPIO_InitStruct.Alternate = GPIO_AF12_SDMMC1;
  HAL_GPIO_Init(uSD_CMD_GPIO_Port, &GPIO_InitStruct);

  /*Configure GPIO pins : uSD_D2_Pin uSD_D3_Pin uSD_CLK_Pin uSD_D0_Pin
                           uSD_D1_Pin */
  GPIO_InitStruct.Pin = uSD_D2_Pin|uSD_D3_Pin|uSD_CLK_Pin|uSD_D0_Pin
                          |uSD_D1_Pin;
  GPIO_InitStruct.Mode = GPIO_MODE_AF_PP;
  GPIO_InitStruct.Pull = GPIO_NOPULL;
  GPIO_InitStruct.Speed = GPIO_SPEED_FREQ_VERY_HIGH;
  GPIO_InitStruct.Alternate = GPIO_AF12_SDMMC1;
  HAL_GPIO_Init(GPIOC, &GPIO_InitStruct);

  /*Configure GPIO pins : USB_OTGFS_ID_Pin USB_OTG_FS_DP_Pin USB_OTGFS_DM_Pin */
  GPIO_InitStruct.Pin = USB_OTGFS_ID_Pin|USB_OTG_FS_DP_Pin|USB_OTGFS_DM_Pin;
  GPIO_InitStruct.Mode = GPIO_MODE_AF_PP;
  GPIO_InitStruct.Pull = GPIO_NOPULL;
  GPIO_InitStruct.Speed = GPIO_SPEED_FREQ_VERY_HIGH;
  GPIO_InitStruct.Alternate = GPIO_AF10_OTG_FS;
  HAL_GPIO_Init(GPIOA, &GPIO_InitStruct);

  /*Configure GPIO pin : JOY_SEL_Pin */
  GPIO_InitStruct.Pin = JOY_SEL_Pin;
  GPIO_InitStruct.Mode = GPIO_MODE_OUTPUT_PP;
  GPIO_InitStruct.Pull = GPIO_NOPULL;
  GPIO_InitStruct.Speed = GPIO_SPEED_FREQ_LOW;
  HAL_GPIO_Init(JOY_SEL_GPIO_Port, &GPIO_InitStruct);

  /*Configure GPIO pin : USB_OTGFS_VBUS_Pin */
  GPIO_InitStruct.Pin = USB_OTGFS_VBUS_Pin;
  GPIO_InitStruct.Mode = GPIO_MODE_INPUT;
  GPIO_InitStruct.Pull = GPIO_NOPULL;
  HAL_GPIO_Init(USB_OTGFS_VBUS_GPIO_Port, &GPIO_InitStruct);

  /*Configure GPIO pins : ARD_14_Pin ARD_15_Pin */
  GPIO_InitStruct.Pin = ARD_14_Pin|ARD_15_Pin;
  GPIO_InitStruct.Mode = GPIO_MODE_AF_OD;
  GPIO_InitStruct.Pull = GPIO_NOPULL;
  GPIO_InitStruct.Speed = GPIO_SPEED_FREQ_VERY_HIGH;
  GPIO_InitStruct.Alternate = GPIO_AF4_I2C3;
  HAL_GPIO_Init(GPIOG, &GPIO_InitStruct);

  /*Configure GPIO pin : STMOD_INT_Pin */
  GPIO_InitStruct.Pin = STMOD_INT_Pin;
  GPIO_InitStruct.Mode = GPIO_MODE_IT_RISING;
  GPIO_InitStruct.Pull = GPIO_NOPULL;
  HAL_GPIO_Init(STMOD_INT_GPIO_Port, &GPIO_InitStruct);

  /*Configure GPIO pins : DFDATIN3_Pin DF_CKOUT_Pin */
  GPIO_InitStruct.Pin = DFDATIN3_Pin|DF_CKOUT_Pin;
  GPIO_InitStruct.Mode = GPIO_MODE_AF_PP;
  GPIO_InitStruct.Pull = GPIO_NOPULL;
  GPIO_InitStruct.Speed = GPIO_SPEED_FREQ_LOW;
  GPIO_InitStruct.Alternate = GPIO_AF6_DFSDM1;
  HAL_GPIO_Init(GPIOC, &GPIO_InitStruct);

  /*Configure GPIO pins : ARD_D0_Pin ARD_D1_Pin */
  GPIO_InitStruct.Pin = ARD_D0_Pin|ARD_D1_Pin;
  GPIO_InitStruct.Mode = GPIO_MODE_AF_PP;
  GPIO_InitStruct.Pull = GPIO_NOPULL;
  GPIO_InitStruct.Speed = GPIO_SPEED_FREQ_VERY_HIGH;
  GPIO_InitStruct.Alternate = GPIO_AF8_LPUART1;
  HAL_GPIO_Init(GPIOC, &GPIO_InitStruct);

  /*Configure GPIO pins : ARD_A2_Pin ARD_A1_Pin */
  GPIO_InitStruct.Pin = ARD_A2_Pin|ARD_A1_Pin;
  GPIO_InitStruct.Mode = GPIO_MODE_ANALOG_ADC_CONTROL;
  GPIO_InitStruct.Pull = GPIO_NOPULL;
  HAL_GPIO_Init(GPIOC, &GPIO_InitStruct);

  /*Configure GPIO pins : ARD_A4_Pin ARD_A0_Pin */
  GPIO_InitStruct.Pin = ARD_A4_Pin|ARD_A0_Pin;
  GPIO_InitStruct.Mode = GPIO_MODE_ANALOG_ADC_CONTROL;
  GPIO_InitStruct.Pull = GPIO_NOPULL;
  HAL_GPIO_Init(GPIOA, &GPIO_InitStruct);

  /*Configure GPIO pin : STMOD_PWM_Pin */
  GPIO_InitStruct.Pin = STMOD_PWM_Pin;
  GPIO_InitStruct.Mode = GPIO_MODE_AF_PP;
  GPIO_InitStruct.Pull = GPIO_NOPULL;
  GPIO_InitStruct.Speed = GPIO_SPEED_FREQ_LOW;
  GPIO_InitStruct.Alternate = GPIO_AF1_TIM2;
  HAL_GPIO_Init(STMOD_PWM_GPIO_Port, &GPIO_InitStruct);

  /*Configure GPIO pin : SPI2_CS_Pin */
  GPIO_InitStruct.Pin = SPI2_CS_Pin;
  GPIO_InitStruct.Mode = GPIO_MODE_OUTPUT_PP;
  GPIO_InitStruct.Pull = GPIO_NOPULL;
  GPIO_InitStruct.Speed = GPIO_SPEED_FREQ_LOW;
  HAL_GPIO_Init(SPI2_CS_GPIO_Port, &GPIO_InitStruct);

  /*Configure GPIO pin : ARD_D5_Pin */
  GPIO_InitStruct.Pin = ARD_D5_Pin;
  GPIO_InitStruct.Mode = GPIO_MODE_AF_PP;
  GPIO_InitStruct.Pull = GPIO_NOPULL;
  GPIO_InitStruct.Speed = GPIO_SPEED_FREQ_LOW;
  GPIO_InitStruct.Alternate = GPIO_AF2_TIM5;
  HAL_GPIO_Init(ARD_D5_GPIO_Port, &GPIO_InitStruct);

  /*Configure GPIO pin : DSI_TE_Pin */
  GPIO_InitStruct.Pin = DSI_TE_Pin;
  GPIO_InitStruct.Mode = GPIO_MODE_AF_PP;
  GPIO_InitStruct.Pull = GPIO_NOPULL;
  GPIO_InitStruct.Speed = GPIO_SPEED_FREQ_LOW;
  GPIO_InitStruct.Alternate = GPIO_AF11_DSI;
  HAL_GPIO_Init(DSI_TE_GPIO_Port, &GPIO_InitStruct);

  /*Configure GPIO pin : DCMI_HSYNC_Pin */
  GPIO_InitStruct.Pin = DCMI_HSYNC_Pin;
  GPIO_InitStruct.Mode = GPIO_MODE_AF_PP;
  GPIO_InitStruct.Pull = GPIO_NOPULL;
  GPIO_InitStruct.Speed = GPIO_SPEED_FREQ_LOW;
  GPIO_InitStruct.Alternate = GPIO_AF10_DCMI;
  HAL_GPIO_Init(DCMI_HSYNC_GPIO_Port, &GPIO_InitStruct);

  /*Configure GPIO pin : ARD_A3_Pin */
  GPIO_InitStruct.Pin = ARD_A3_Pin;
  GPIO_InitStruct.Mode = GPIO_MODE_ANALOG_ADC_CONTROL;
  GPIO_InitStruct.Pull = GPIO_NOPULL;
  HAL_GPIO_Init(ARD_A3_GPIO_Port, &GPIO_InitStruct);

  /*Configure GPIO pin : MFX_WAKEUP_Pin */
  GPIO_InitStruct.Pin = MFX_WAKEUP_Pin;
  GPIO_InitStruct.Mode = GPIO_MODE_OUTPUT_PP;
  GPIO_InitStruct.Pull = GPIO_NOPULL;
  GPIO_InitStruct.Speed = GPIO_SPEED_FREQ_LOW;
  HAL_GPIO_Init(MFX_WAKEUP_GPIO_Port, &GPIO_InitStruct);

  /*Configure GPIO pin : DFDATIN1_Pin */
  GPIO_InitStruct.Pin = DFDATIN1_Pin;
  GPIO_InitStruct.Mode = GPIO_MODE_AF_PP;
  GPIO_InitStruct.Pull = GPIO_NOPULL;
  GPIO_InitStruct.Speed = GPIO_SPEED_FREQ_LOW;
  GPIO_InitStruct.Alternate = GPIO_AF6_DFSDM1;
  HAL_GPIO_Init(DFDATIN1_GPIO_Port, &GPIO_InitStruct);

}

/* USER CODE BEGIN 4 */

/**
  * @brief  printf() retarget hook (see syscalls.c: _write() calls this per
  *         character). Left as a no-op on purpose: huart2 also carries the
  *         binary AI protocol (sync byte, input floats, output bytes) to the
  *         PC script, and any debug text sent on the same line would corrupt
  *         that stream. Without this definition, __io_putchar stays an
  *         unresolved weak symbol (resolves to address 0): the very first
  *         printf() call (in MX_X_CUBE_AI_Init) branches to address 0 and
  *         HardFaults, freezing the board in HardFault_Handler's while(1)
  *         before it ever reaches the main loop.
  */
int __io_putchar(int ch)
{
  return ch;
}

/* USER CODE END 4 */

void Error_Handler(void)
{
  __disable_irq();
  while (1)
  {
  }
}
